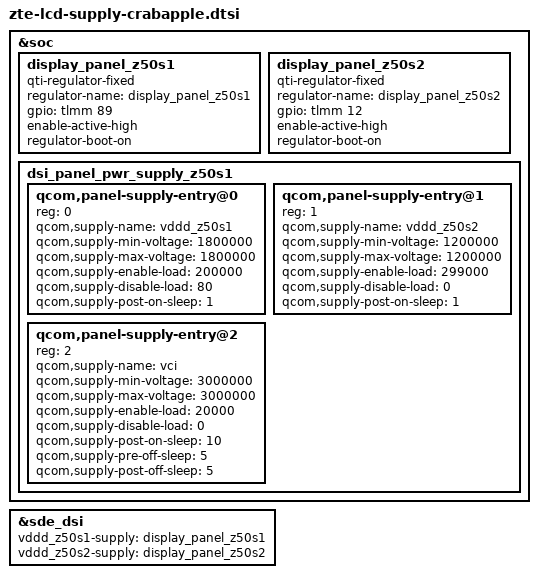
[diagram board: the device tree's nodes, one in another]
#include "kalama-sde-display-mtp.dtsi"
#include "dsi-panel-zte-bf068-nt377705-6p78-dsc-cmd.dtsi"

&soc {
	/* add by zte for lcd new panel begin*/
	display_panel_z50s1: display_panel_z50s1 {
		compatible = "qti-regulator-fixed";
		regulator-name = "display_panel_z50s1";
		gpio = <&tlmm 89 0>;
		enable-active-high;
		regulator-boot-on;
	};
	display_panel_z50s2: display_panel_z50s2 {
		compatible = "qti-regulator-fixed";
		regulator-name = "display_panel_z50s2";
		gpio = <&tlmm 12 0>;
		enable-active-high;
		regulator-boot-on;
	};
	dsi_panel_pwr_supply_z50s1: dsi_panel_pwr_supply_z50s1 {
		#address-cells = <1>;
		#size-cells = <0>;

		qcom,panel-supply-entry@0 {
			reg = <0>;
			qcom,supply-name = "vddd_z50s1";
			qcom,supply-min-voltage = <1800000>;
			qcom,supply-max-voltage = <1800000>;
			qcom,supply-enable-load = <200000>;
			qcom,supply-disable-load = <80>;
			qcom,supply-post-on-sleep = <1>;
		};

		qcom,panel-supply-entry@1 {
			reg = <1>;
			qcom,supply-name = "vddd_z50s2";
			qcom,supply-min-voltage = <1200000>;
			qcom,supply-max-voltage = <1200000>;
			qcom,supply-enable-load = <299000>;
			qcom,supply-disable-load = <0>;
			qcom,supply-post-on-sleep = <1>;
		};

		qcom,panel-supply-entry@2 {
			reg = <2>;
			qcom,supply-name = "vci";
			qcom,supply-min-voltage = <3000000>;
			qcom,supply-max-voltage = <3000000>;
			qcom,supply-enable-load = <20000>;
			qcom,supply-disable-load = <0>;
			qcom,supply-post-on-sleep = <10>;
			qcom,supply-pre-off-sleep = <5>;
			qcom,supply-post-off-sleep = <5>;
		};
	};
};
&sde_dsi {
	vddd_z50s1-supply = <&display_panel_z50s1>;
	vddd_z50s2-supply = <&display_panel_z50s2>;
};
